# PIC32CM2532JH01048 device description
Architecture: CORTEX-M0PLUS; Family: PIC32CM; Series: PIC32CMJH01
Registers are 32-bit, read-write, reset 0x0 unless marked. A register's access mark holds for its fields unless they carry their own. Offsets are from the block's base; [hi:lo] are bit positions; {n}, {i} and the like mark numbered series; 'fields as' and 'values as' point back to an identical list.

## CAN_XIDFE — Extended Message ID Filter Element
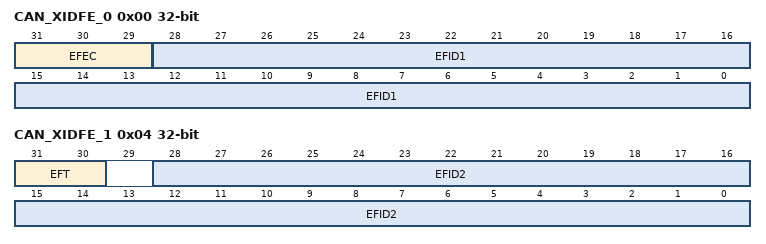
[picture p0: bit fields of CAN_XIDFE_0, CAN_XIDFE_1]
0x00 CAN_XIDFE_0 reset not defined — Extended Message ID Filter Element 0
  [31:29] EFEC — Extended Filter Element Configuration
    0=DISABLE (Disable filter element); 1=STF0M (Store in Rx FIFO 0 if filter match); 2=STF1M (Store in Rx FIFO 1 if filter match); 3=REJECT (Reject ID if filter match); 4=PRIORITY (Set priority if filter match); 5=PRIF0M (Set priority and store in FIFO 0 if filter match); 6=PRIF1M (Set priority and store in FIFO 1 if filter match); 7=STRXBUF (Store into Rx Buffer)
  [28:0] EFID1 — Extended Filter ID 1
0x04 CAN_XIDFE_1 reset not defined — Extended Message ID Filter Element 1
  [31:30] EFT — Extended Filter Type
    0=RANGEM (Range filter from EFID1 to EFID2); 1=DUAL (Dual ID filter for EFID1 or EFID2); 2=CLASSIC (Classic filter); 3=RANGE (Range filter from EFID1 to EFID2 with no XIDAM mask)
  [28:0] EFID2 — Extended Filter ID 2

## CCL — Configurable Custom Logic
Instances: CCL 0x42005800
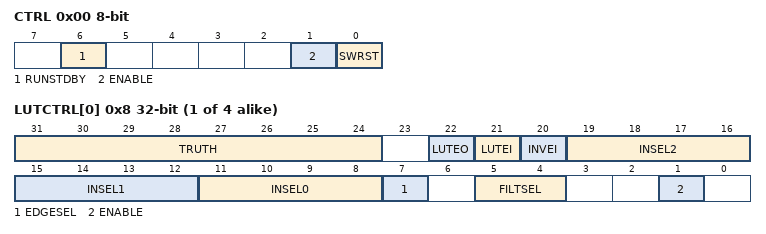
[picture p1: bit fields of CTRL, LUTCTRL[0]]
0x00 CTRL 8-bit — Control
  [6] RUNSTDBY — Run in Standby
    0=DISABLE (Generic clock is not required in standby sleep mode); 1=ENABLE (Generic clock is required in standby sleep mode)
  [1] ENABLE
    0=DISABLE (The peripheral is disabled); 1=ENABLE (The peripheral is enabled)
  [0] SWRST — Software Reset
    0=DISABLE (The peripheral is not reset); 1=ENABLE (The peripheral is reset)
{0x4+i} SEQCTRL[{i}] (i=0..1) 8-bit — SEQ Control x
  [3:0] SEQSEL — Sequential Selection
    0=DISABLE (Sequential logic is disabled); 1=DFF (D flip flop); 2=JK (JK flip flop); 3=LATCH (D latch); 4=RS (RS latch)
{0x8+4i} LUTCTRL[{i}] (i=0..3) — LUT Control x
  [31:24] TRUTH — Truth Value
  [22] LUTEO — LUT Event Output Enable
    0=DISABLE (LUT event output is disabled); 1=ENABLE (LUT event output is enabled)
  [21] LUTEI — LUT Event Input Enable
    0=DISABLE (LUT incoming event is disabled); 1=ENABLE (LUT incoming event is enabled)
  [20] INVEI — Inverted Event Input Enable
    0=NORMAL (Incoming event is not inverted); 1=INVERTED (Incoming event is inverted)
  [19:16] INSEL2 — Input Selection 2
    0=MASK (Masked input); 1=FEEDBACK (Feedback input source); 2=LINK (Linked LUT input source); 3=EVENT (Event input source); 4=IO (I/O pin input source); 5=AC (AC input source); 6=TC (TC input source); 7=ALTTC (Alternate TC input source); 8=TCC (TCC input source); 9=SERCOM (SERCOM input source); 10=ALT2TC (Second alternative TC input source); 11=ASYNCEVENT (Asynchronous event input source)
  [15:12] INSEL1 — Input Selection 1
    values as INSEL2
  [11:8] INSEL0 — Input Selection 0
    values as INSEL2
  [7] EDGESEL — Edge Selection
    0=DISABLE (Edge detector is disabled); 1=ENABLE (Edge detector is enabled)
  [5:4] FILTSEL — Filter Selection
    0=DISABLE (Filter disabled); 1=SYNCH (Synchronizer enabled); 2=FILTER (Filter enabled)
  [1] ENABLE — LUT Enable
    0=DISABLE (LUT block is disabled); 1=ENABLE (LUT block is enabled)

## DAC — Digital Analog Converter
Instances: DAC 0x42005000
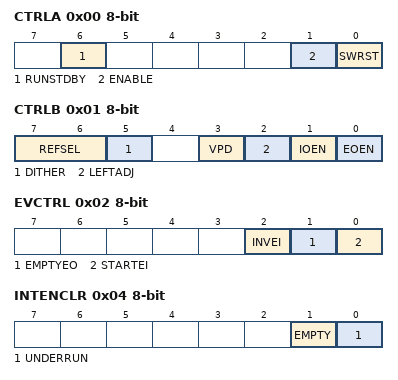
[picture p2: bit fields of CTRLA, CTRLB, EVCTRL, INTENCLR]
0x00 CTRLA 8-bit (WSYNC) — Control A
  [6] RUNSTDBY — Run in Standby
  [1] ENABLE
  [0] SWRST — Software Reset
0x01 CTRLB 8-bit — Control B
  [7:6] REFSEL — Reference Selection
    0=INTREF (Internal Voltage Reference); 1=VDDANA (Analog Voltage Supply); 2=VREFA (External Voltage Reference A (shared with ADC))
  [5] DITHER — Dither Enable
  [3] VPD — Voltage Pump Disable
  [2] LEFTADJ — Left Adjusted Data
  [1] IOEN — Internal Output Enable
  [0] EOEN — External Output Enable
0x02 EVCTRL 8-bit — Event Control
  [2] INVEI — Invert Event Input
  [1] EMPTYEO — Data Buffer Empty Event Output
  [0] STARTEI — Start Conversion Event Input
0x04 INTENCLR 8-bit (atomic clear) — Interrupt Enable Clear
  [1] EMPTY — Data Buffer Empty Interrupt Enable
  [0] UNDERRUN — Underrun Interrupt Enable
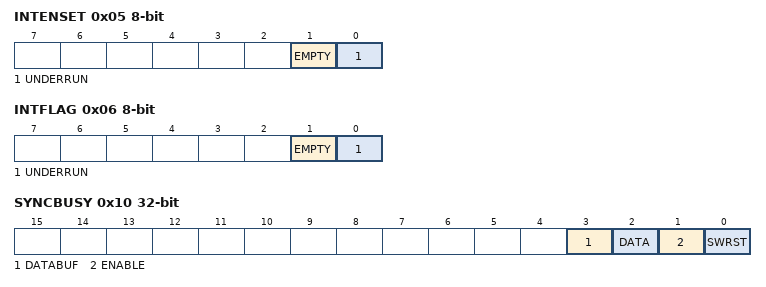
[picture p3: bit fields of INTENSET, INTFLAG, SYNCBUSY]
0x05 INTENSET 8-bit (atomic set) — Interrupt Enable Set
  fields as INTENCLR
0x06 INTFLAG 8-bit (atomic clear) — Interrupt Flag Status and Clear
  [1] EMPTY — Data Buffer Empty
  [0] UNDERRUN
0x07 STATUS 8-bit ro
  [0] READY — DAC Ready
0x08 DATA 16-bit wo (WSYNC)
  [15:0] DATA — Data value to be converted
0x0C DATABUF 16-bit wo (WSYNC) — Data Buffer
0x10 SYNCBUSY ro — Synchronization Busy
  [3] DATABUF — Data Buffer
  [2] DATA
  [1] ENABLE — DAC Enable Status
  [0] SWRST — Software Reset
0x14 DBGCTRL 8-bit — Debug Control
  [0] DBGRUN — Debug Run

## Notices in the file
Copyright (c) 2019 Microchip Technology Inc.
SPDX-License-Identifier: Apache-2.0
Licensed under the Apache License, Version 2.0 (the "License");
you may not use this file except in compliance with the License.
You may obtain a copy of the License at
http://www.apache.org/licenses/LICENSE-2.0
Unless required by applicable law or agreed to in writing, software
distributed under the License is distributed on an "AS IS" BASIS,
WITHOUT WARRANTIES OR CONDITIONS OF ANY KIND, either express or implied.
See the License for the specific language governing permissions and
limitations under the License.
